AUTOSAR XML (schema 4-2-1)
package /RootP_BSWC_NvDM
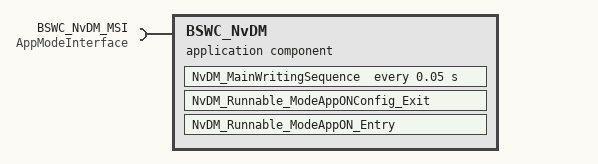
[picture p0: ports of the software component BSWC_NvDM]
  application sw component type BSWC_NvDM
    require port BSWC_NvDM_MSI: required-interface=AppModeInterface
    behavior IB_BSWC_NvDM: data-type-mapping=ApplicationModeMapping, handle-termination-and-restart=NO-SUPPORT
      timing event NvDM_MainWritingSequence_Cyclic: start-on-event=NvDM_MainWritingSequence, period=0.05
        disabled-mode:
          BSWC_NvDM_MSI.AppMode.APP_WAKEUP
          BSWC_NvDM_MSI.AppMode.APP_OFF
          BSWC_NvDM_MSI.AppMode.APP_SYNC_INIT1
          BSWC_NvDM_MSI.AppMode.APP_SYNC_INIT2
          BSWC_NvDM_MSI.AppMode.APP_CONFIG
      swc mode switch event NvDM_Runnable_ModeAppON_Entry_ENTRY: start-on-event=NvDM_Runnable_ModeAppON_Entry, activation=ON-ENTRY, mode=BSWC_NvDM_MSI.AppMode.APP_SYNC_INIT2
      swc mode switch event NvDM_Runnable_ModeAppONConfig_Exit_EXIT: start-on-event=NvDM_Runnable_ModeAppONConfig_Exit, activation=ON-EXIT, mode=BSWC_NvDM_MSI.AppMode.APP_ON
      runnable NvDM_MainWritingSequence
      runnable NvDM_Runnable_ModeAppONConfig_Exit
      runnable NvDM_Runnable_ModeAppON_Entry
package /RootP_Implementatation
  swc implementation Implementatation_BSWC_NvDM: programming-language=C, sw-version=1.0.0, vendor-id=1, behavior=IB_BSWC_NvDM
    code-descriptors:
      code SRC: artifact-descriptors=autosar-engineering-object={short-label=EngObject, category=SWSRC}
    resource consumption Resources
